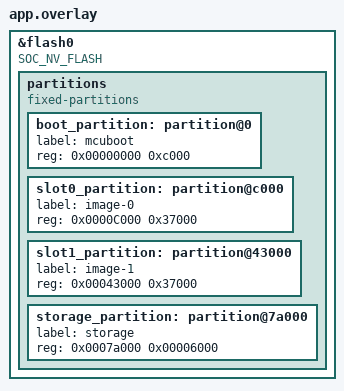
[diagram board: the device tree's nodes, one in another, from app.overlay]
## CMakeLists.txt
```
# SPDX-License-Identifier: Apache-2.0

cmake_minimum_required(VERSION 3.20.0)
find_package(Zephyr REQUIRED HINTS $ENV{ZEPHYR_BASE})
project(nvmp)

FILE(GLOB app_sources src/*.c)
target_sources(app PRIVATE ${app_sources})
```

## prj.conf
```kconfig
CONFIG_ZTEST=y
CONFIG_FLASH=y
CONFIG_FLASH_PAGE_LAYOUT=y
CONFIG_NVMP=y
CONFIG_NVMP_FLASH=y
CONFIG_ZTEST_NEW_API=y
```

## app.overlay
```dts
/*
 * Copyright (c) 2023, Laczen.
 *
 * SPDX-License-Identifier: Apache-2.0
 */

&flash0 {

	compatible = "SOC_NV_FLASH", "zephyr,nvmp_flash";

	partitions {
		compatible = "fixed-partitions", "zephyr,nvmp-partitions";
		#address-cells = <1>;
		#size-cells = <1>;

		boot_partition: partition@0 {
			label = "mcuboot";
			reg = <0x00000000 0xc000>;
		};
		slot0_partition: partition@c000 {
			label = "image-0";
			reg = <0x0000C000 0x37000>;
		};
		slot1_partition: partition@43000 {
			label = "image-1";
			reg = <0x00043000 0x37000>;
		};
		storage_partition: partition@7a000 {
			label = "storage";
			reg = <0x0007a000 0x00006000>;
		};
	};
};
```

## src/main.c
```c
/*
 * Copyright (c) 2017 Nordic Semiconductor ASA
 * Copyright (c) 2015 Runtime Inc
 * Copyright (c) 2020 Gerson Fernando Budke <nandojve@gmail.com>
 *
 * SPDX-License-Identifier: Apache-2.0
 */

#include <zephyr/ztest.h>
#include <zephyr/nvmp/nvmp.h>

/**
 * @brief Test nvmp_api()
 */
ZTEST(nvmp, test_nvmp_api_slot1)
{
	const struct nvmp_info *info = NVMP_GET(slot1_partition);
	uint8_t wd[256];
	uint8_t rd[256];
	off_t off = 0;
	int rc;

	(void)memset(wd, 0xa5, sizeof(wd));

	rc = nvmp_write(info, off, wd, sizeof(wd));
	zassert_true(rc == 0, "write() fail");

	/* read it back */
	rc = nvmp_read(info, off, rd, sizeof(rd));
	zassert_true(rc == 0, "read() fail");

	rc = memcmp(wd, rd, sizeof(wd));
	zassert_true(rc == 0, "read data != write data");

	/* erase it */
	rc = nvmp_erase(info, 0, nvmp_get_size(info));
	zassert_true(rc == 0, "read data != write data");
}

ZTEST(nvmp, test_nvmp_api_slot0)
{
	const struct nvmp_info *info = NVMP_GET(slot0_partition);
	uint8_t wd[256];
	uint8_t rd[256];
	off_t off = 0;
	int rc;

	(void)memset(wd, 0xa5, sizeof(wd));

	rc = nvmp_write(info, off, wd, sizeof(wd));
	zassert_true(rc == 0, "write() fail");

	/* read it back */
	rc = nvmp_read(info, off, rd, sizeof(rd));
	zassert_true(rc == 0, "read() fail");

	rc = memcmp(wd, rd, sizeof(wd));
	zassert_true(rc == 0, "read data != write data");

	/* erase it */
	rc = nvmp_erase(info, 0, nvmp_get_size(info));
	zassert_true(rc == 0, "read data != write data");
}

ZTEST_SUITE(nvmp, NULL, NULL, NULL, NULL, NULL);
```
